# S6E1C1xB register map
Vendor: Cypress; File version: 2.1
CPU: CM0PLUS r0p1, little endian, no MPU, no FPU, 2 interrupt priority bits
Registers are 32-bit, read-write, reset 0x0 unless marked. A register's access mark holds for its fields unless they carry their own. Offsets are from the block's base; [hi:lo] are bit positions; {n}, {i} and the like mark numbered series; 'fields as' and 'values as' point back to an identical list.

## MFS0 — Multi-function Serial Interface 0
Base 0x40038000
Same registers: MFS1 0x40038100, MFS3 0x40038300, MFS7 0x40038700
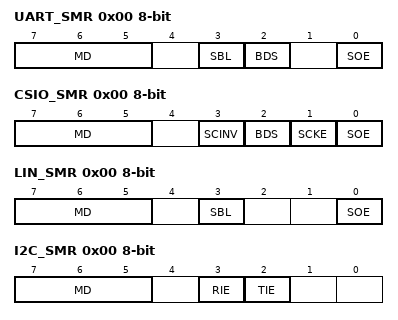
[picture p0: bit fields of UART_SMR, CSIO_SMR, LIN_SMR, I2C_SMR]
0x00 UART_SMR 8-bit (UART view) — Serial Mode Register [BHW]
  [7:5] MD — Operation mode set bit
  [3] SBL — Stop bit length select bit
  [2] BDS — Transfer direction select bit
  [0] SOE — Serial data output enable bit
0x00 CSIO_SMR 8-bit (CSIO view) — Serial Mode Register [BHW]
  [7:5] MD — Operation mode set bits
  [3] SCINV — Serial clock invert bit
  [2] BDS — Transfer direction select bit
  [1] SCKE — Master mode serial clock output enable bit
  [0] SOE — Serial data output enable bit
0x00 LIN_SMR 8-bit (LIN view) — Serial Mode Register [BHW]
  [7:5] MD — Operation mode setting bits
  [3] SBL — Stop bit length select bit
  [0] SOE — Serial data output enable bit
0x00 I2C_SMR 8-bit (I2C view) — Serial Mode Register [BHW]
  [7:5] MD — Operation mode set bits
  [3] RIE — Received interrupt enable bit
  [2] TIE — Transmit interrupt enable bit
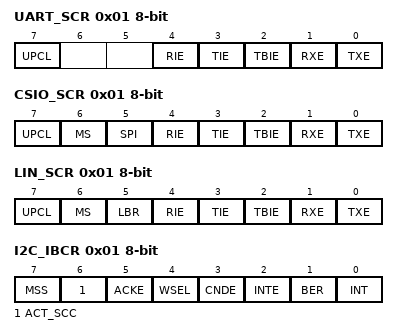
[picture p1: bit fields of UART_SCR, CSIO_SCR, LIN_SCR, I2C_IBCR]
0x01 UART_SCR 8-bit (UART view) — Serial Control Register [BHW]
  [7] UPCL — Programmable Clear bit
  [4] RIE — Received interrupt enable bit
  [3] TIE — Transmit interrupt enable bit
  [2] TBIE — Transmit bus idle interrupt enable bit
  [1] RXE — Received operation enable bit
  [0] TXE — Transmission operation enable bit
0x01 CSIO_SCR 8-bit (CSIO view) — Serial Control Register [BHW]
  [7] UPCL — Programmable clear bit
  [6] MS — Master/Slave function select bit
  [5] SPI — SPI corresponding bit
  [4] RIE — Received interrupt enable bit
  [3] TIE — Transmit interrupt enable bit
  [2] TBIE — Transmit bus idle interrupt enable bit
  [1] RXE — Data received enable bit
  [0] TXE — Data transmission enable bit
0x01 LIN_SCR 8-bit (LIN view) — Serial Control Register [BHW]
  [7] UPCL — Programmable clear bit
  [6] MS — Master/Slave function select bit
  [5] LBR — LIN Break Field setting bit (valid in master mode only)
  [4] RIE — Received interrupt enable bit
  [3] TIE — Transmit interrupt enable bit
  [2] TBIE — Transmit bus idle interrupt enable bit
  [1] RXE — Data reception enable bit
  [0] TXE — Data transmission enable bit
0x01 I2C_IBCR 8-bit (I2C view) — I2C Bus Control Register [BHW]
  [7] MSS — Master/slave select bit
  [6] ACT_SCC — Operation flag/iteration start condition generation bit
  [5] ACKE — Data byte acknowledge enable bit
  [4] WSEL — Wait selection bit
  [3] CNDE — Condition detection interrupt enable bit
  [2] INTE — Interrupt enable bit
  [1] BER ro — Bus error flag bit
  [0] INT — Interrupt flag bit
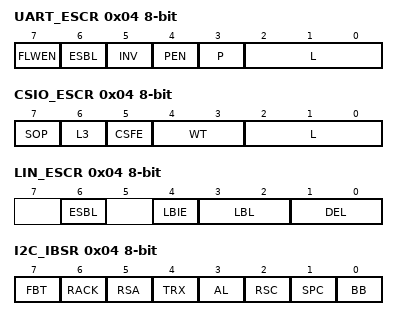
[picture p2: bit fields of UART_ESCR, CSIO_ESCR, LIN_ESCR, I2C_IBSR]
0x04 UART_ESCR 8-bit (UART view) — Extended Communication Control Register [BHW]
  [7] FLWEN — Flow control enable bit
  [6] ESBL — Extension stop bit length select bit
  [5] INV — Inverted serial data format bit
  [4] PEN — Parity enable bit (only functions in operation mode 0)
  [3] P — Parity select bit (only functions in operation mode 0)
  [2:0] L — Data length select bit
0x04 CSIO_ESCR 8-bit (CSIO view) — Extended Communication Control Register [BHW]
  [7] SOP — Serial output pin set bit
  [6] L3 — Bit3 of Data length select bits
  [5] CSFE — Serial Chip Select Format enable bit
  [4:3] WT — Data transmit/received wait select bits
  [2:0] L — Bit0-2 of Data length select bits
0x04 LIN_ESCR 8-bit (LIN view) — Extended Communication Control Register [BHW]
  [6] ESBL — Extended stop bit length select bit
  [4] LBIE — LIN Break field detect interrupt enable bit
  [3:2] LBL — LIN Break field length select bits (valid in master mode only)
  [1:0] DEL — LIN Break delimiter length select bits (valid in master mode only)
0x04 I2C_IBSR 8-bit (I2C view) — I2C Bus Status Register [BHW]
  [7] FBT ro — First byte bit
  [6] RACK ro — Acknowledge flag bit
  [5] RSA ro — Reserved address detection bit
  [4] TRX ro — Data direction bit
  [3] AL ro — Arbitration lost bit
  [2] RSC — Iteration start condition check bit
  [1] SPC — Stop condition check bit
  [0] BB ro — Bus state bit
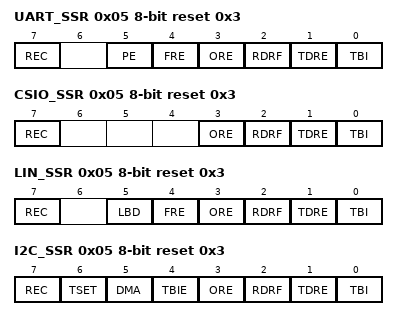
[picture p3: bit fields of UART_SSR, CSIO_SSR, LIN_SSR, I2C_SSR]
0x05 UART_SSR 8-bit reset 0x3 (UART view) — Serial Status Register [BHW]
  [7] REC — Received error flag clear bit
  [5] PE ro — Parity error flag bit (only functions in operation mode 0)
  [4] FRE ro — Framing error flag bit
  [3] ORE ro — Overrun error flag bit
  [2] RDRF ro — Received data full flag bit
  [1] TDRE ro — Transmit data empty flag bit
  [0] TBI ro — Transmit bus idle flag
0x05 CSIO_SSR 8-bit reset 0x3 (CSIO view) — Serial Status Register [BHW]
  [7] REC — Received error flag clear bit
  [3] ORE ro — Overrun error flag bit
  [2] RDRF ro — Received data full flag bit
  [1] TDRE ro — Transmit data empty flag bit
  [0] TBI ro — Transmit bus idle flag bit
0x05 LIN_SSR 8-bit reset 0x3 (LIN view) — Serial Status Register [BHW]
  [7] REC — Received Error flag clear bit
  [5] LBD — LIN Break field detection flag bit
  [4] FRE ro — Framing error flag bit
  [3] ORE ro — Overrun error flag bit
  [2] RDRF ro — Received data full flag bit
  [1] TDRE ro — Transmit data empty flag bit
  [0] TBI ro — Transmit bus idle flag bit
0x05 I2C_SSR 8-bit reset 0x3 (I2C view) — Serial Status Register [BHW]
  [7] REC — Received error flag clear bit
  [6] TSET — Transmit empty flag set bit
  [5] DMA — DMA mode enable bit
  [4] TBIE — Transmit bus idle interrupt enable bit (Effective only when DMA mode is enabled)
  [3] ORE ro — Overrun error flag bit
  [2] RDRF ro — Received data full flag bit
  [1] TDRE ro — Transmit data empty flag bit
  [0] TBI ro — Transmit bus idle flag bit (Effective only when DMA mode is enabled)
0x08 UART_RDR 16-bit ro (UART view) — Received Data Register [HW]
  [8:0] D — Data
0x08 UART_TDR 16-bit wo reset 0x1FF (UART view) — Transmit Data Register [HW]
  [8:0] D — Data
0x08 CSIO_RDR 16-bit ro (CSIO view) — Received Data Register [HW]
  [15:0] D — Data
0x08 CSIO_TDR 16-bit wo reset 0xFFFF (CSIO view) — Transmit Data Register [HW]
  [15:0] D — Data
0x08 LIN_RDR 16-bit ro (LIN view) — Received Data Register [HW]
  [7:0] D — Data
0x08 LIN_TDR 16-bit wo reset 0xFF (LIN view) — Transmit Data Register [HW]
  [7:0] D — Data
0x08 I2C_RDR 16-bit ro (I2C view) — Received Data Register [HW]
  [7:0] D — Data
0x08 I2C_TDR 16-bit wo reset 0xFF (I2C view) — Transmit Data Register [HW]
  [7:0] D — Data
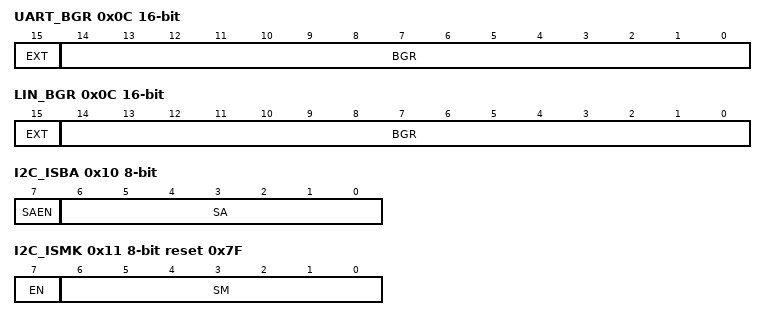
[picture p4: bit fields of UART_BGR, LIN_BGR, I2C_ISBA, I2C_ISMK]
0x0C UART_BGR 16-bit (UART view) — Baud Rate Generator Registers [BHW]
  [15] EXT — External clock select bit
  [14:0] BGR — Baud Rate Generator Register
0x0C CSIO_BGR 16-bit (CSIO view) — Baud Rate Generator Registers [BHW]
  [14:0] BGR — Baud Rate Generator Register
0x0C LIN_BGR 16-bit (LIN view) — Baud Rate Generator Registers [BHW]
  fields as UART_BGR
0x0C I2C_BGR 16-bit (I2C view) — Baud Rate Generator Registers [BHW]
  [14:0] BGR — Baud Rate Generator Register
0x10 I2C_ISBA 8-bit (I2C view) — 7-bit Slave Address Register [BHW]
  [7] SAEN — Slave address enable bit
  [6:0] SA — 7-bit slave address
0x11 I2C_ISMK 8-bit reset 0x7F (I2C view) — 7-bit Slave Address Mask Register [BHW]
  [7] EN — I2C interface operation enable bit
  [6:0] SM — Slave address mask bits
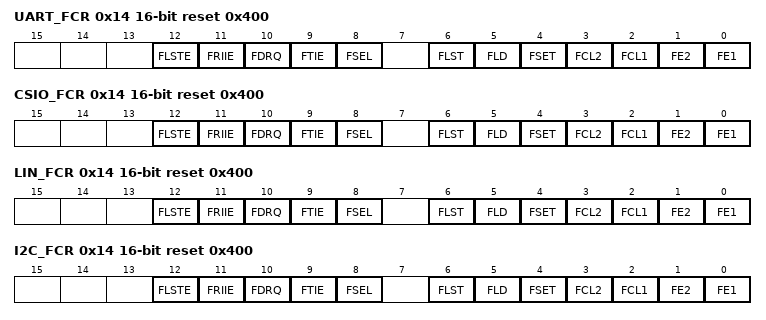
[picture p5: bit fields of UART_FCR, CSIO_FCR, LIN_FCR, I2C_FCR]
0x14 UART_FCR 16-bit reset 0x400 (UART view) — FIFO Control Register 0 and 1 [BHW]
  [12] FLSTE — Re-transmission data lost detect enable bit
  [11] FRIIE — Received FIFO idle detection enable bit
  [10] FDRQ — Transmit FIFO data request bit
  [9] FTIE — Transmit FIFO interrupt enable bit
  [8] FSEL — FIFO select bit
  [6] FLST ro — FIFO re-transmit data lost flag bit
  [5] FLD — FIFO pointer reload bit
  [4] FSET — FIFO pointer save bit
  [3] FCL2 — FIFO2 reset bit
  [2] FCL1 — FIFO1 reset bit
  [1] FE2 — FIFO2 operation enable bit
  [0] FE1 — FIFO1 operation enable bit
0x14 CSIO_FCR 16-bit reset 0x400 (CSIO view) — FIFO Control Register 0 and 1 [BHW]
  fields as UART_FCR
0x14 LIN_FCR 16-bit reset 0x400 (LIN view) — FIFO Control Register 0 and 1 [BHW]
  fields as UART_FCR
0x14 I2C_FCR 16-bit reset 0x400 (I2C view) — FIFO Control Register 0 and 1 [BHW]
  fields as UART_FCR
0x18 UART_FBYTE1 8-bit (UART view) — FIFO Byte Register 1 [BHW]
  [7:0] FD — data count in FIFO
0x18 CSIO_FBYTE1 8-bit (CSIO view) — FIFO Byte Register 1 [BHW]
  [7:0] FD — data count in FIFO
0x18 LIN_FBYTE1 8-bit (LIN view) — FIFO Byte Register 1 [BHW]
  [7:0] FD — data count in FIFO
0x18 I2C_FBYTE1 8-bit (I2C view) — FIFO Byte Register 1 [BHW]
  [7:0] FD — data count in FIFO
0x19 UART_FBYTE2 8-bit (UART view) — FIFO Byte Register 2 [BHW]
  [7:0] FD — data count in FIFO
0x19 CSIO_FBYTE2 8-bit (CSIO view) — FIFO Byte Register 2 [BHW]
  [7:0] FD — data count in FIFO
0x19 LIN_FBYTE2 8-bit (LIN view) — FIFO Byte Register 2 [BHW]
  [7:0] FD — data count in FIFO
0x19 I2C_FBYTE2 8-bit (I2C view) — FIFO Byte Register 2 [BHW]
  [7:0] FD — data count in FIFO
0x1C CSIO_SCSTR0 8-bit (CSIO view) — Serial Chip Select Timing Register 0 [BHW]
  [7:0] CSHD — Serial Chip Select Hold Delay bits
0x1D CSIO_SCSTR1 8-bit (CSIO view) — Serial Chip Select Timing Register 1 [BHW]
  [7:0] CSSU — Serial Chip Select Setup Delay bits
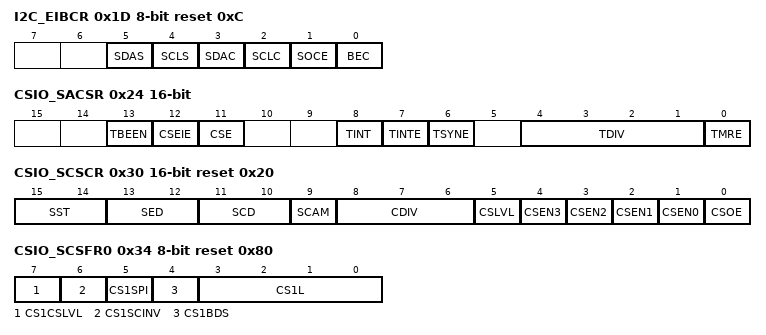
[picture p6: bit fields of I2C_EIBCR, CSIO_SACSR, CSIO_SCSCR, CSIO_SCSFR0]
0x1D I2C_EIBCR 8-bit reset 0xC (I2C view) — Extension I2C Bus Control Register [BHW]
  [5] SDAS ro — SDA status bit
  [4] SCLS ro — SCL status bit
  [3] SDAC — SDA output control bit
  [2] SCLC — SCL output control bit
  [1] SOCE — Serial output enabled bit
  [0] BEC — Bus error control bit
0x20 CSIO_SCSTR32 16-bit (CSIO view) — Serial Chip Select Timing Registers 2/3 [BHW]
  [15:0] CSDS — Serial Chip Deselect bits
0x24 CSIO_SACSR 16-bit (CSIO view) — Serial Support Control Register [BHW]
  [13] TBEEN — Transfer Byte Error Enable bit
  [12] CSEIE — Chip Select Error Interupt Enable bit
  [11] CSE — Chip Select Error Flag
  [8] TINT — Timer Interrupt Flag
  [7] TINTE — Timer Interrupt Enable bit
  [6] TSYNE — Synchronous Transmission Enable bit
  [4:1] TDIV — Timer Operation Clock Division bit
  [0] TMRE — Serial Timer Enable bit
0x28 CSIO_STMR 16-bit ro (CSIO view) — Serial Timer Register [BHW]
  [15:0] TM — Timer Data bits
0x2C CSIO_STMCR 16-bit (CSIO view) — Serial Timer Comparison Register [BHW]
  [15:0] TC — Compare bits
0x30 CSIO_SCSCR 16-bit reset 0x20 (CSIO view) — Serial Chip Select Control Status Register [BHW]
  [15:14] SST — Serial Chip Select Active Start bit
  [13:12] SED — Serial Chip Select Active End bit
  [11:10] SCD — Serial Chip Select Active Display bit
  [9] SCAM — Serial Chip Select Active Hold bit
  [8:6] CDIV — Serial Chip Select Timing Operation Clock Division bit
  [5] CSLVL — Serial Chip Select Level Setting bit
  [n+1] CSEN{n} (n=0..3) — Serial Chip Select Enable bit
  [0] CSOE — Serial Chip Select Output Enable bit
0x34 CSIO_SCSFR0 8-bit reset 0x80 (CSIO view) — Serial Chip Select Format Register 0 [BHW]
  [7] CS1CSLVL — Serial Chip Select 1 Level Setting bit
  [6] CS1SCINV — Serial Clock Invert bit of Serial Chip Select 1
  [5] CS1SPI — SPI corresponding bit of Serial Chip Select 1
  [4] CS1BDS — Transfer direction select bit of Serial Chip Select 1
  [3:0] CS1L — Data length select bits of Serial Chip Select 1
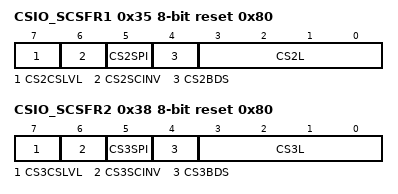
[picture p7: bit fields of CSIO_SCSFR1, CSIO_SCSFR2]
0x35 CSIO_SCSFR1 8-bit reset 0x80 (CSIO view) — Serial Chip Select Format Register 1 [BHW]
  [7] CS2CSLVL — Serial Chip Select 2 Level Setting bit
  [6] CS2SCINV — Serial Clock Invert bit of Serial Chip Select 2
  [5] CS2SPI — SPI corresponding bit of Serial Chip Select 2
  [4] CS2BDS — Transfer direction select bit of Serial Chip Select 2
  [3:0] CS2L — Data length select bits of Serial Chip Select 2
0x38 CSIO_SCSFR2 8-bit reset 0x80 (CSIO view) — Serial Chip Select Format Register 3 [BHW]
  [7] CS3CSLVL — Serial Chip Select 3 Level Setting bit
  [6] CS3SCINV — Serial Clock Invert bit of Serial Chip Select 3
  [5] CS3SPI — SPI corresponding bit of Serial Chip Select 3
  [4] CS3BDS — Transfer direction select bit of Serial Chip Select 3
  [3:0] CS3L — Data length select bits of Serial Chip Select 3
0x3C CSIO_TBYTE0 8-bit (CSIO view) — Transfer Byte Register 0 [BHW]
0x3D CSIO_TBYTE1 8-bit (CSIO view) — Transfer Byte Register 1 [BHW]
0x40 CSIO_TBYTE2 8-bit (CSIO view) — Transfer Byte Register 2 [BHW]
0x41 CSIO_TBYTE3 8-bit (CSIO view) — Transfer Byte Register 3 [BHW]

## MFS4 — Multi-function Serial Interface 4
Base 0x40038400
Same registers: MFS6 0x40038600
Registers as MFS0; these are added or differ:
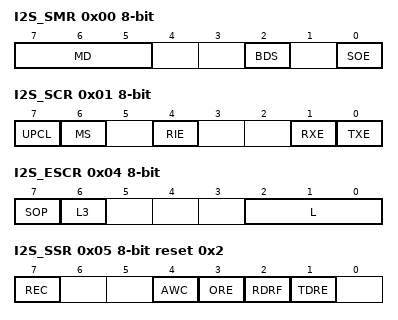
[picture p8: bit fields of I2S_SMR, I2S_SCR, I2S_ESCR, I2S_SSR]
0x00 I2S_SMR 8-bit (I2S view) — Serial Mode Register [BHW]
  [7:5] MD — Oeration mode set bits
  [2] BDS — Transfer direction select bit
  [0] SOE — Serial data output enable bit
0x01 I2S_SCR 8-bit (I2S view) — Serial Control Register [BHW]
  [7] UPCL — Programmable clear bit
  [6] MS — Master/Slave function select bit
  [4] RIE — Received interrupt enable bit
  [1] RXE — Data received enable bit
  [0] TXE — Data transmission enable bit
0x04 I2S_ESCR 8-bit (I2S view) — Extended Communication Control Register [BHW]
  [7] SOP — Serial output pin set bit
  [6] L3 — Data length select bit 3
  [2:0] L — Data length select bits
0x05 I2S_SSR 8-bit reset 0x2 (I2S view) — Serial Status Register [BHW]
  [7] REC — Received error flag clear bit
  [4] AWC — FIFO access width set
  [3] ORE ro — Overrun error flag bit
  [2] RDRF ro — Received data full flag bit
  [1] TDRE ro — Transmit data empty flag bit
0x08 I2S_RDR ro (I2S view) — Received Data Register [HW]
0x08 I2S_TDR wo reset 0xFFFFFFFF (reset mask 0xFFFFFFF) (I2S view) — Transmit Data Register [HW]
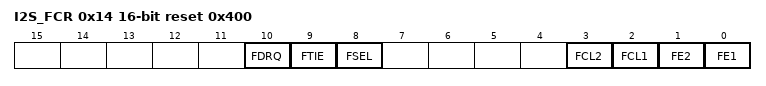
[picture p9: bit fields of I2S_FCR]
0x14 I2S_FCR 16-bit reset 0x400 (I2S view) — FIFO Control Register 0 and 1 [BHW]
  [10] FDRQ — Transmit FIFO data request bit
  [9] FTIE — Transmit FIFO interrupt enable bit
  [8] FSEL — FIFO select bit
  [3] FCL2 — FIFO2 reset bit
  [2] FCL1 — FIFO1 reset bit
  [1] FE2 — FIFO2 operation enable bit
  [0] FE1 — FIFO1 operation enable bit
0x18 I2S_FBYTE1 8-bit (I2S view) — FIFO Byte Register 1 [BHW]
  [7:0] FD — data count in FIFO
0x19 I2S_FBYTE2 8-bit (I2S view) — FIFO Byte Register 2 [BHW]
  [7:0] FD — data count in FIFO
